# DAC0_1.0 register map
Vendor: Texas Instruments
Peripheral module from a debugger description file (folder mspm0g1x0x_g3x0x).
Registers are 32-bit, read-write, no defined reset value unless marked. A register's access mark holds for its fields unless they carry their own. Offsets are as the file gives them; lines under a group give offsets from that group; [hi:lo] are bit positions; {n}, {i} and the like mark numbered series; 'fields as' and 'values as' point back to an identical list; <NAME> marks a mode.

## DAC0
0x400 DAC0_FSUB_0 — Subscriber Port 0
  [3:0] CHANID — 0 = disconnected. others = connected to channel_ID = CHANID.
    0=MNIMUM (0 is an allowed value, signifying that the event is unconnected); 0=UNCONNECTED (A value of 0 specifies that the event is not connected); 15=MAXIMUM (Consult your device datasheet as the actual allowed maximum may be less than 15.)
0x404 DAC0_FSUB_1 — Subscriber Port 1
  fields as DAC0_FSUB_0
0x444 DAC0_FPUB_1 — Publisher port 1
  fields as DAC0_FSUB_0
0x800 DAC0_GPRCM group
  0x00 DAC0_PWREN — Power enable
    [0] ENABLE — Enable the power
      0=DISABLE (Disable Power); 1=ENABLE (Enable Power)
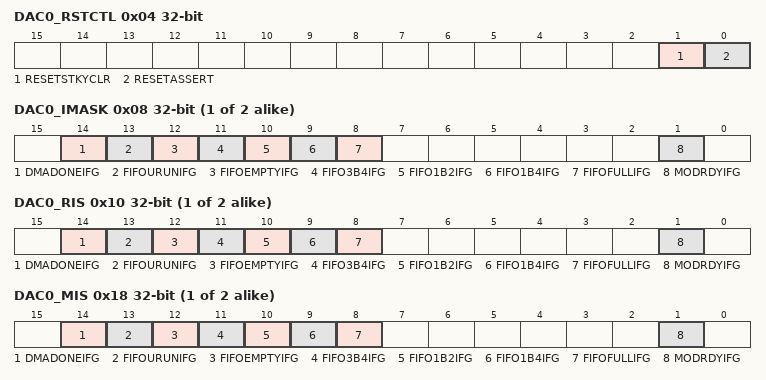
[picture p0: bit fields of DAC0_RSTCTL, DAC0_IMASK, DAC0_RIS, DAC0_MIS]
  0x04 DAC0_RSTCTL — Reset Control
    [1] RESETSTKYCLR — Clear the RESETSTKY bit in the STAT register
      0=NOP (Writing 0 has no effect); 1=CLR (Clear reset sticky bit)
    [0] RESETASSERT — Assert reset to the peripheral
      0=NOP (Writing 0 has no effect); 1=ASSERT (Assert reset)
  0x14 DAC0_STAT ro — Status Register
    [16] RESETSTKY — This bit indicates, if the peripheral was reset, since this bit was cleared by RESETSTKYCLR in the RSTCTL register
      0=NORES (The peripheral has not been reset since this bit was last cleared by RESETSTKYCLR in the RSTCTL register); 1=RESET (The peripheral was reset since the last bit clear)
{0x1020+0x30*i} DAC0_INT_EVENT[{i}] (i=0..1) group
  0x00 DAC0_IIDX ro — Interrupt index
    [3:0] STAT — Interrupt index status
      0=NO_INTR (No pending interrupt); 2=MODRDYIFG (Module ready interrupt); 9=FIFOFULLIFG (FIFO full interrupt); 10=FIFO1B4IFG (FIFO one fourth empty interrupt); 11=FIFO1B2IFG (FIFO half empty interrupt); 12=FIFO3B4IFG (FIFO three fourth empty interrupt); 13=FIFOEMPTYIFG (FIFO empty interrupt); 14=FIFOURUNIFG (FIFO underrun interrupt); 15=DMADONEIFG (DMA done interrupt)
  0x08 DAC0_IMASK — Interrupt mask
    [all] fields
      0=CLR (Interrupt is masked out); 1=SET (Interrupt will request an interrupt service routine and corresponding bit in MIS will be set)
    [14] DMADONEIFG — Masks DMADONEIFG
    [13] FIFOURUNIFG — Masks FIFOURUNIFG
    [12] FIFOEMPTYIFG — Masks FIFOEMPTYIFG
    [11] FIFO3B4IFG — Masks FIFO3B4IFG
    [10] FIFO1B2IFG — Masks FIFO1B2IFG
    [9] FIFO1B4IFG — Masks FIFO1B4IFG
    [8] FIFOFULLIFG — Masks FIFOFULLIFG
    [1] MODRDYIFG — Masks MODRDYIFG
  0x10 DAC0_RIS — Raw interrupt status
    [14] DMADONEIFG — Raw interrupt status for DMADONEIFG
      0=CLR (DMA done condition did not occur); 1=SET (DMA done condition occurred)
    [13] FIFOURUNIFG — Raw interrupt status for FIFOURUNIFG
      0=CLR (FIFO underrun condition did not occur); 1=SET (FIFO underrun condition occurred)
    [12] FIFOEMPTYIFG — Raw interrupt status for FIFOEMPTYIFG
      0=CLR (FIFO empty condition did not occur); 1=SET (FIFO empty condition occurred)
    [11] FIFO3B4IFG — Raw interrupt status for FIFO3B4IFG
      0=CLR (FIFO three fourth empty condition did not occur); 1=SET (FIFO three fourth empty condition occurred)
    [10] FIFO1B2IFG — Raw interrupt status for FIFO1B2IFG
      0=CLR (FIFO half empty condition did not occur); 1=SET (FIFO half empty condition occurred)
    [9] FIFO1B4IFG — Raw interrupt status for FIFO1B4IFG
      0=CLR (FIFO one fourth empty condition did not occur); 1=SET (FIFO one fourth empty condition occurred)
    [8] FIFOFULLIFG — Raw interrupt status for FIFOFULLIFG
      0=CLR (FIFO full condition did not occur); 1=SET (FIFO full condition occurred)
    [1] MODRDYIFG — Raw interrupt status for MODRDYIFG
      0=CLR (DAC module ready event did not occur); 1=SET (DAC module ready event occurred)
  0x18 DAC0_MIS — Masked interrupt status
    [14] DMADONEIFG — Masked interrupt status for DMADONEIFG
      0=CLR (DMADONEIFG does not request an interrupt service routine); 1=SET (DMADONEIFG requests an interrupt service routine)
    [13] FIFOURUNIFG — Masked interrupt status for FIFOURUNIFG
      0=CLR (FIFOURUNIFG does not request an interrupt service routine); 1=SET (FIFOURUNIFG requests an interrupt service routine)
    [12] FIFOEMPTYIFG — Masked interrupt status for FIFOEMPTYIFG
      0=CLR (FIFOEMPTYIFG does not request an interrupt service routine); 1=SET (FIFOEMPTYIFG requests an interrupt service routine)
    [11] FIFO3B4IFG — Masked interrupt status for FIFO3B4IFG
      0=CLR (FIFO3B4IFG does not request an interrupt service routine); 1=SET (FIFO3B4IFG requests an interrupt service routine)
    [10] FIFO1B2IFG — Masked interrupt status for FIFO1B2IFG
      0=CLR (FIFO1B2IFG does not request an interrupt service routine); 1=SET (FIFO1B2IFG requests an interrupt service routine)
    [9] FIFO1B4IFG — Masked interrupt status for FIFO1B4IFG
      0=CLR (FIFO1B4IFG does not request an interrupt service routine); 1=SET (FIFO1B4IFG requests an interrupt service routine)
    [8] FIFOFULLIFG — Masked interrupt status for FIFOFULLIFG
      0=CLR (FIFOFULLIFG does not request an interrupt service routine); 1=SET (FIFOFULLIFG requests an interrupt service routine)
    [1] MODRDYIFG — Masked interrupt status for MODRDYIFG
      0=CLR (MODRDYIFG does not request an interrupt service routine); 1=SET (MODRDYIFG requests an interrupt service routine)
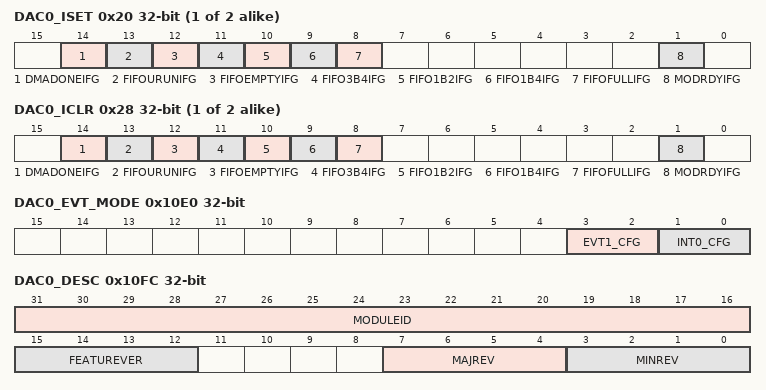
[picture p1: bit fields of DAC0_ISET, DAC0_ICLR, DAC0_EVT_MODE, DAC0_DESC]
  0x20 DAC0_ISET — Interrupt set
    [14] DMADONEIFG — Sets DMADONEIFG in RIS register
      0=NO_EFFECT (Writing a 0 has no effect); 1=SET (RIS bit corresponding to DMADONEIFG is set)
    [13] FIFOURUNIFG — Sets FIFOURUNIFG in RIS register
      0=NO_EFFECT (Writing a 0 has no effect); 1=SET (RIS bit corresponding to FIFOURUNIFG is set)
    [12] FIFOEMPTYIFG — Sets FIFOEMPTYIFG in RIS register
      0=NO_EFFECT (Writing a 0 has no effect); 1=SET (RIS bit corresponding to FIFOEMPTYIFG is set)
    [11] FIFO3B4IFG — Sets FIFO3B4IFG in RIS register
      0=NO_EFFECT (Writing a 0 has no effect); 1=SET (RIS bit corresponding to FIFO3B4IFG is set)
    [10] FIFO1B2IFG — Sets FIFO1B2IFG in RIS register
      0=NO_EFFECT (Writing a 0 has no effect); 1=SET (RIS bit corresponding to FIFO1B2IFG is set)
    [9] FIFO1B4IFG — Sets FIFO1B4IFG in RIS register
      0=NO_EFFECT (Writing a 0 has no effect); 1=SET (RIS bit corresponding to FIFO1B4IFG is set)
    [8] FIFOFULLIFG — Sets FIFOFULLIFG in RIS register
      0=NO_EFFECT (Writing a 0 has no effect); 1=SET (RIS bit corresponding to FIFOFULLIFG is set)
    [1] MODRDYIFG — Sets MODRDYIFG in RIS register
      0=NO_EFFECT (Writing a 0 has no effect); 1=SET (RIS bit corresponding to MODRDYIFG is set)
  0x28 DAC0_ICLR — Interrupt clear
    [14] DMADONEIFG — Clears DMADONEIFG in RIS register
      0=NO_EFFECT (Writing a 0 has no effect); 1=CLR (RIS bit corresponding to DMADONEIFG is cleared)
    [13] FIFOURUNIFG — Clears FIFOURUNIFG in RIS register
      0=NO_EFFECT (Writing a 0 has no effect); 1=CLR (RIS bit corresponding to FIFOURUNIFG is cleared)
    [12] FIFOEMPTYIFG — Clears FIFOEMPTYIFG in RIS register
      0=NO_EFFECT (Writing a 0 has no effect); 1=CLR (RIS bit corresponding to FIFOEMPTYIFG is cleared)
    [11] FIFO3B4IFG — Clears FIFO3B4IFG in RIS register
      0=NO_EFFECT (Writing a 0 has no effect); 1=CLR (RIS bit corresponding to FIFO3B4IFG is cleared)
    [10] FIFO1B2IFG — Clears FIFO1B2IFG in RIS register
      0=NO_EFFECT (Writing a 0 has no effect); 1=CLR (RIS bit corresponding to FIFO1B2IFG is cleared)
    [9] FIFO1B4IFG — Clears FIFO1B4IFG in RIS register
      0=NO_EFFECT (Writing a 0 has no effect); 1=CLR (RIS bit corresponding to FIFO1B4IFG is cleared)
    [8] FIFOFULLIFG — Clears FIFOFULLIFG in RIS register
      0=NO_EFFECT (Writing a 0 has no effect); 1=CLR (RIS bit corresponding to FIFOFULLIFG is cleared)
    [1] MODRDYIFG — Clears MODRDYIFG in RIS register
      0=NO_EFFECT (Writing a 0 has no effect); 1=CLR (RIS bit corresponding to MODRDYIFG is cleared)
0x10E0 DAC0_EVT_MODE ro — Event Mode
  [3:2] EVT1_CFG — Event line mode select for event corresponding to [IPSTANDARD.INT_EVENT][0]
    0=DISABLE (The interrupt or event line is disabled.); 1=SOFTWARE (Event handled by software. Software must clear the associated RIS flag.); 2=HARDWARE (Event handled by hardware. The hardware (another module) clears automatically the associated RIS flag.)
  [1:0] INT0_CFG — Event line mode select for event corresponding to [IPSTANDARD.INT_EVENT][0]
    values as EVT1_CFG
0x10FC DAC0_DESC ro — Module Description
  [31:16] MODULEID — Module identification contains a unique peripheral identification number. The assignments are maintained in a central database for all of the platform modules to ensure uniqueness.
  [15:12] FEATUREVER — Feature Set for the module *instance*
  [7:4] MAJREV — Major rev of the IP
  [3:0] MINREV — Minor rev of the IP
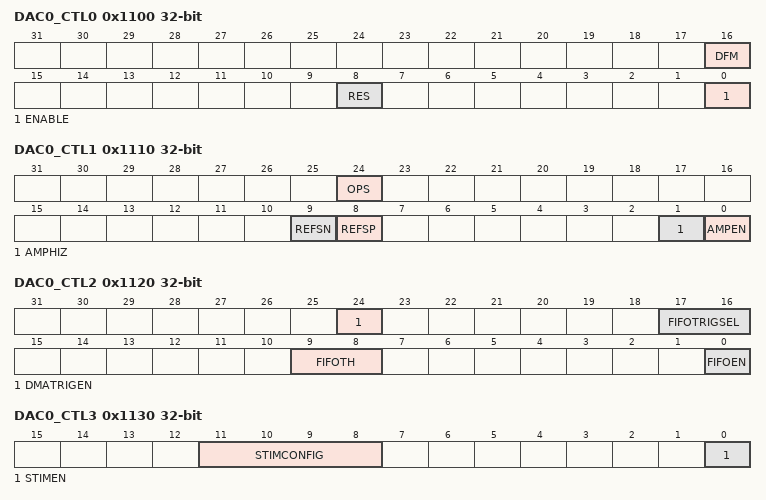
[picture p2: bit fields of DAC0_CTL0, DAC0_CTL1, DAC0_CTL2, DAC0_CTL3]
0x1100 DAC0_CTL0 — Control 0
  [16] DFM — This bit defines the DAC input data format.
    0=BINARY (Straight binary); 1=TWOS_COMP (Twos complement)
  [8] RES — These bits define the DAC output voltage resolution.
    0=_8BITS (8-bits resolution); 1=_12BITS (12-bit resolution)
  [0] ENABLE — This bit enables the DAC module.
    0=CLR (DAC is disabled); 1=SET (DAC is enabled)
0x1110 DAC0_CTL1 — Control 1
  [24] OPS — These bits select the DAC output on device pin.
    0=NOC0 (No connect. Both DAC output switches are open.); 1=OUT0 (OUT0 output is selected)
  [9] REFSN — This bit selects the DAC voltage reference source + input.
    0=VEREFN (VEREFN pin as VR-); 1=VSSA (Analog supply (VSSA) as VR-)
  [8] REFSP — This bit selects the DAC voltage reference source + input.
    0=VDDA (Analog supply (VDDA) as VR+); 1=VEREFP (VEREFP pin as VR+)
  [1] AMPHIZ — AMPHIZ - amplifier output value 0 : amplifier output is high impedance 1 : amplifier output is pulled down to ground
    0=HIZ (HiZ when disable); 1=PULLDOWN (dacout pulldown when disable)
  [0] AMPEN — AMP_EN - output amplifier enabled or disabled 0 : disabled 1 : enabled
    0=DISABLE; 1=ENABLE
0x1120 DAC0_CTL2 — Control 2
  [24] DMATRIGEN — This bit enables the DMA trigger generation mechanism. When this bit is set along with FIFOEN, the DMA trigger is generated based on the empty FIFO locations qualified by FIFOTH settings. This bit needs to be cleared by SW to stop further DMA triggers
    0=CLR (DMA trigger generation mechanism is disabled); 1=SET (DMA trigger generation mechanism is enabled)
  [17:16] FIFOTRIGSEL — These bits select the source for FIFO read trigger. When the selected FIFO read trigger is asserted, the data from FIFO (as indicated by read pointer) is moved into internal DAC data register.
    0=STIM (Sample time generator output); 1=TRIG0 (Hardware trigger-0 from event fabric); 2=TRIG1 (Hardware trigger-1 from event fabric); 3=SPARE (Reserved - unimplemented)
  [9:8] FIFOTH — These bits determine the FIFO threshold. In case of DMA based operation, DAC generates new DMA trigger when the number of empty locations in FIFO match the selected FIFO threshold level. In case of CPU based operation, the FIFO threshold bits are don't care and FIFO level is directly indicated through the respective bits in the RIS register.
    0=LOW (One fourth of the FIFO locations are empty); 1=MED (Half of the FIFO locations are empty); 2=HIGH (Three fourth of the FIFO locations are empty); 3=SPARE (Reserved value. Defaults to same effect as FIFOTH = 0 (One fourth of the FIFO locations are empty).)
  [0] FIFOEN — This bit enables the FIFO and the FIFO hardware control state machine.
    0=CLR (FIFO is disabled); 1=SET (FIFO is enabled)
0x1130 DAC0_CTL3 — Control 3
  [11:8] STIMCONFIG — These bits are used to configure the trigger rate from the sample time generator. The STIMCONFIG values 10 to 15 are reserved and default to same effect as value 0 (500SPS).
    0=_500SPS (Trigger rate is 500 sps (clock divide value is 4000)); 1=_1KSPS (Trigger rate is 1 ksps (clock divide value is 2000)); 2=_2KSPS (Trigger rate is 2 ksps (clock divide value is 1000)); 3=_4KSPS (Trigger rate is 4 ksps (clock divide value is 500)); 4=_8KSPS (Trigger rate is 8 ksps (clock divide value is 250)); 5=_16KSPS (Trigger rate is 16 ksps (clock divide value is 125)); 6=_100KSPS (Trigger rate is 100 ksps (clock divide value is 20)); 7=_200KSPS (Trigger rate is 200 ksps (clock divide value is 10)); 8=_500KSPS (Trigger rate is 500 ksps (clock divide value is 4)); 9=_1MSPS (Trigger rate is 1 Msps (clock divide value is 2))
  [0] STIMEN — This bit enables the sample time generator.
    0=CLR (Sample time generator is disabled); 1=SET (Sample time generator is enabled)
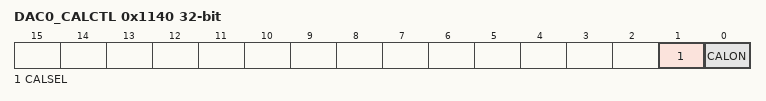
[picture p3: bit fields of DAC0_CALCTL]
0x1140 DAC0_CALCTL — Calibration control
  [1] CALSEL — This bit is used to select between factory trim or self calibration trim.
    0=FACTORYTRIM (Factory Trim Calibration Values are used when calibration is enabled); 1=SELFCALIBRATIONTRIM (Self Calibration Trim Values are used when calibration is enabled)
  [0] CALON — This bit when set initiates the DAC offset error calibration sequence and is automatically reset when the offset error calibration completes.
    0=INACTIVE (Offset error calibration is not active); 1=ACTIVE (Initiate offset error calibration or offset error calibration is already in progress)
0x1160 DAC0_CALDATA ro — Calibration data
  [6:0] DATA — DAC offset error calibration data. The DAC offset error calibration data is represented in twos complement format providing a range of 64 to +63. This is read-only bit, reflecting the calibration data. Writing to this register will have no effect, it will not change the calibration value.
0x1200 DAC0_DATA0 — Data 0
  [11:0] DATA_VALUE — This is the data written for digital to analog conversion.
